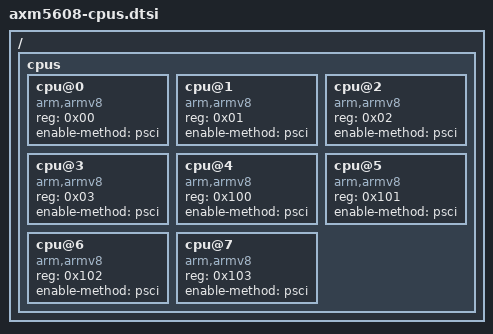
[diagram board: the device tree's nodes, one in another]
// SPDX-License-Identifier: GPL-2.0
// Copyright (C) 2021 INTEL Corporation

/ {
	cpus {
		#address-cells = <1>;
		#size-cells = <0>;

		cpu@0 {
			device_type = "cpu";
			compatible = "arm,armv8";
			reg = <0x00>;
			enable-method = "psci";
		};

		cpu@1 {
			device_type = "cpu";
			compatible = "arm,armv8";
			reg = <0x01>;
			enable-method = "psci";
		};

		cpu@2 {
			device_type = "cpu";
			compatible = "arm,armv8";
			reg = <0x02>;
			enable-method = "psci";
		};

		cpu@3 {
			device_type = "cpu";
			compatible = "arm,armv8";
			reg = <0x03>;
			enable-method = "psci";
		};

		cpu@4 {
			device_type = "cpu";
			compatible = "arm,armv8";
			reg = <0x100>;
			enable-method = "psci";
		};

		cpu@5 {
			device_type = "cpu";
			compatible = "arm,armv8";
			reg = <0x101>;
			enable-method = "psci";
		};

		cpu@6 {
			device_type = "cpu";
			compatible = "arm,armv8";
			reg = <0x102>;
			enable-method = "psci";
		};

		cpu@7 {
			device_type = "cpu";
			compatible = "arm,armv8";
			reg = <0x103>;
			enable-method = "psci";
		};
	};
};
